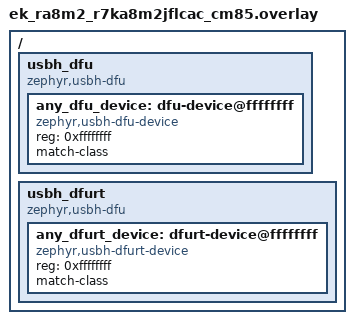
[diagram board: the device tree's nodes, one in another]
/*
 * Copyright (c) 2026 Renesas Electronics Corporation
 *
 * SPDX-License-Identifier: Apache-2.0
 */

/ {
	usbh_dfu: usbh_dfu {
		compatible = "zephyr,usbh-dfu";

		#address-cells = <1>;
		#size-cells = <0>;

		any_dfu_device: dfu-device@ffffffff {
			compatible = "zephyr,usbh-dfu-device";
			reg = <0xffffffff>;
			status="okay";
			match-class;
		};
	};

	usbh_dfurt: usbh_dfurt {
		compatible = "zephyr,usbh-dfu";

		#address-cells = <1>;
		#size-cells = <0>;

		any_dfurt_device: dfurt-device@ffffffff {
			compatible = "zephyr,usbh-dfurt-device";
			reg = <0xffffffff>;
			status="okay";
			match-class;
		};
	};
};
